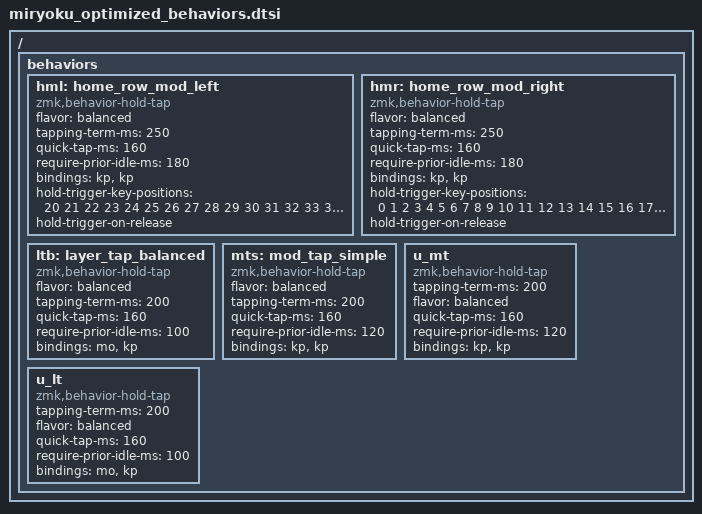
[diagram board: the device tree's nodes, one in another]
// Optimized ZMK Hold-Tap Behaviors for Miryoku
// Balanced reliability and responsiveness for medium-speed typing

/ {
  behaviors {
    // Home Row Modifiers - Left Hand (HML)
    // Optimized for reliability with bilateral enforcement
    hml: home_row_mod_left {
      compatible = "zmk,behavior-hold-tap";
      #binding-cells = <2>;
      flavor = "balanced";
      tapping-term-ms = <250>;
      quick-tap-ms = <160>;
      require-prior-idle-ms = <180>;
      bindings = <&kp>, <&kp>;
      // Trigger on right hand keys (positions 20-39 for Corne)
      hold-trigger-key-positions = <20 21 22 23 24 25 26 27 28 29 30 31 32 33 34 35 36 37 38 39>;
      hold-trigger-on-release;
    };

    // Home Row Modifiers - Right Hand (HMR)
    // Optimized for reliability with bilateral enforcement
    hmr: home_row_mod_right {
      compatible = "zmk,behavior-hold-tap";
      #binding-cells = <2>;
      flavor = "balanced";
      tapping-term-ms = <250>;
      quick-tap-ms = <160>;
      require-prior-idle-ms = <180>;
      bindings = <&kp>, <&kp>;
      // Trigger on left hand keys (positions 0-19 for Corne)
      hold-trigger-key-positions = <0 1 2 3 4 5 6 7 8 9 10 11 12 13 14 15 16 17 18 19>;
      hold-trigger-on-release;
    };

    // Layer Tap - Balanced (LTB)
    // Optimized for responsive layer switching
    ltb: layer_tap_balanced {
      compatible = "zmk,behavior-hold-tap";
      #binding-cells = <2>;
      flavor = "balanced";
      tapping-term-ms = <200>;
      quick-tap-ms = <160>;
      require-prior-idle-ms = <100>;
      bindings = <&mo>, <&kp>;
    };

    // Mod Tap - Simple (MTS)
    // For non-home-row modifiers that don't need positional logic
    mts: mod_tap_simple {
      compatible = "zmk,behavior-hold-tap";
      #binding-cells = <2>;
      flavor = "balanced";
      tapping-term-ms = <200>;
      quick-tap-ms = <160>;
      require-prior-idle-ms = <120>;
      bindings = <&kp>, <&kp>;
    };

    // Fallback behaviors for compatibility
    u_mt: u_mt {
      compatible = "zmk,behavior-hold-tap";
      #binding-cells = <2>;
      tapping-term-ms = <200>;
      flavor = "balanced";
      quick-tap-ms = <160>;
      require-prior-idle-ms = <120>;
      bindings = <&kp>, <&kp>;
    };

    u_lt: u_lt {
      compatible = "zmk,behavior-hold-tap";
      #binding-cells = <2>;
      tapping-term-ms = <200>;
      flavor = "balanced";
      quick-tap-ms = <160>;
      require-prior-idle-ms = <100>;
      bindings = <&mo>, <&kp>;
    };
  };
};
